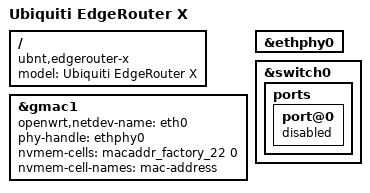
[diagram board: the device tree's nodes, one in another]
#include "mt7621_ubnt_edgerouter-x.dtsi"

/ {
	model = "Ubiquiti EdgeRouter X";
	compatible = "ubnt,edgerouter-x", "mediatek,mt7621-soc";
};

&gmac1 {
	status = "okay";
	openwrt,netdev-name = "eth0";
	phy-handle = <&ethphy0>;

	nvmem-cells = <&macaddr_factory_22 0>;
	nvmem-cell-names = "mac-address";
};

&ethphy0 {
	/delete-property/ interrupts;
};

&switch0 {
	ports {
		port@0 {
			status = "disabled";
		};
	};
};
